AUTOSAR XML (schema 4-0-3)
package /AppSwComponent_Dcm/SwComponentType
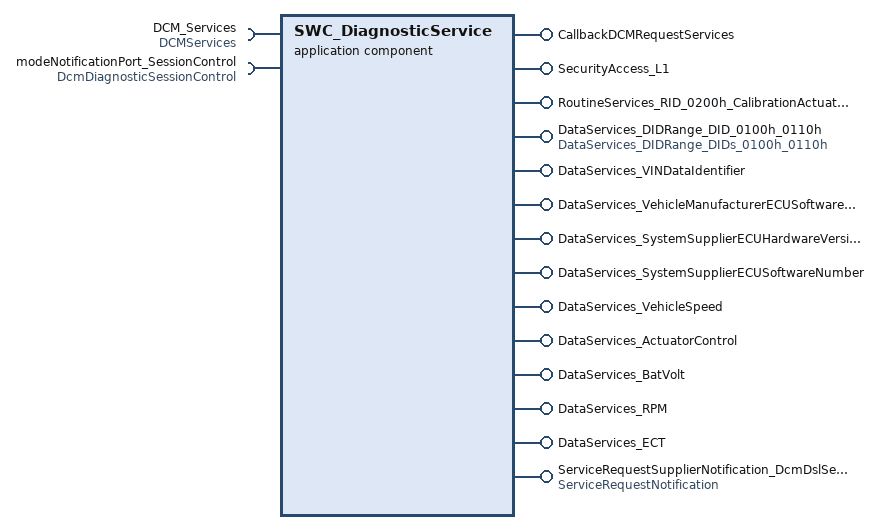
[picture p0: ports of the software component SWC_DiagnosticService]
  application sw component type SWC_DiagnosticService
    4 x provide port:
      CallbackDCMRequestServices: provided-com-specs=[{operation=StartProtocol, queue-length=1}, {operation=StopProtocol, queue-length=1}], provided-interface=CallbackDCMRequestServices
      SecurityAccess_L1: provided-com-specs=[{operation=GetSeed, queue-length=1}, {operation=CompareKey, queue-length=1}], provided-interface=SecurityAccess_L1
      RoutineServices_RID_0200h_CalibrationActuator: provided-interface=RoutineServices_RID_0200h_CalibrationActuator
        provided-com-specs:
          operation=Start, queue-length=1
          operation=Stop, queue-length=1
          operation=RequestResults, queue-length=1
      DataServices_DIDRange_DID_0100h_0110h: provided-interface=DataServices_DIDRange_DIDs_0100h_0110h
        provided-com-specs:
          operation=ReadDidData, queue-length=1
          operation=WriteDidData, queue-length=1
          operation=IsDidAvailable, queue-length=1
    require port DCM_Services: required-com-specs=[GetActiveProtocol, GetSesCtrlType, GetSecurityLevel, ResetToDefaultSession], required-interface=DCMServices
    10 x provide port:
      DataServices_VINDataIdentifier: provided-interface=DataServices_VINDataIdentifier
        provided-com-specs:
          operation=ReadData, queue-length=1
          operation=ConditionCheckRead, queue-length=1
          operation=WriteData, queue-length=1
          operation=GetScalingInformation, queue-length=1
      DataServices_VehicleManufacturerECUSoftwareVersionNumber: provided-com-specs=[{operation=ReadData, queue-length=1}, {operation=ConditionCheckRead, queue-length=1}], provided-interface=DataServices_VehicleManufacturerECUSoftwareVersionNumber
      DataServices_SystemSupplierECUHardwareVersionNumber: provided-com-specs=[{operation=ReadData, queue-length=1}, {operation=ConditionCheckRead, queue-length=1}], provided-interface=DataServices_SystemSupplierECUHardwareVersionNumber
      DataServices_SystemSupplierECUSoftwareNumber: provided-com-specs=[{operation=ReadData, queue-length=1}, {operation=ConditionCheckRead, queue-length=1}], provided-interface=DataServices_SystemSupplierECUSoftwareNumber
      DataServices_VehicleSpeed: provided-interface=DataServices_VehicleSpeed
        provided-com-specs:
          operation=ReadData, queue-length=1
          operation=ConditionCheckRead, queue-length=1
          operation=GetScalingInformation, queue-length=1
      DataServices_ActuatorControl: provided-interface=DataServices_ActuatorControl
        provided-com-specs:
          operation=ConditionCheckRead, queue-length=1
          operation=ReadData, queue-length=1
          operation=ReturnControlToECU, queue-length=1
          operation=ResetToDefault, queue-length=1
          operation=FreezeCurrentState, queue-length=1
          operation=ShortTermAdjustment, queue-length=1
          operation=WriteData, queue-length=1
      DataServices_BatVolt: provided-interface=DataServices_BatVolt
        provided-com-specs:
          operation=ReadData, queue-length=1
          operation=ConditionCheckRead, queue-length=1
          operation=WriteData, queue-length=1
      DataServices_RPM: provided-interface=DataServices_RPM
        provided-com-specs:
          operation=ReadData, queue-length=1
          operation=ConditionCheckRead, queue-length=1
          operation=FreezeCurrentState, queue-length=1
          operation=ReturnControlToECU, queue-length=1
          operation=ShortTermAdjustment, queue-length=1
          operation=WriteData, queue-length=1
      DataServices_ECT: provided-interface=DataServices_ECT
        provided-com-specs:
          operation=ReadData, queue-length=1
          operation=ConditionCheckRead, queue-length=1
          operation=WriteData, queue-length=1
      ServiceRequestSupplierNotification_DcmDslServiceRequestSupplierNotification0: provided-com-specs=[{operation=Confirmation, queue-length=1}, {operation=Indication, queue-length=1}], provided-interface=ServiceRequestNotification
    require port modeNotificationPort_SessionControl: mode-switch-receiver-com-spec{enhanced-mode-api=true, mode-group=DcmDiagnosticSessionControl, supports-asynchronous-mode-switch=true}, required-interface=DcmDiagnosticSessionControl
    behavior InternalBehaviors_DiagnosticService
      44 x operation invoked event:
        OIE_CallbackDCMRequestServices_StartProtocol: start-on-event=CallbackDCMRequestServices_StartProtocol, operation=CallbackDCMRequestServices.StartProtocol
        OIE_CallbackDCMRequestServices_StopProtocol: start-on-event=CallbackDCMRequestServices_StopProtocol, operation=CallbackDCMRequestServices.StopProtocol
        OIE_L1_GetSeed: start-on-event=L1_GetSeed, operation=SecurityAccess_L1.GetSeed
        OIE_L1_CompareKey: start-on-event=L1_CompareKey, operation=SecurityAccess_L1.CompareKey
        OIE_RID_0200h_CalibrationActuator_Start: start-on-event=RID_0200h_CalibrationActuator_Start, operation=RoutineServices_RID_0200h_CalibrationActuator.Start
        OIE_RID_0200h_CalibrationActuator_Stop: start-on-event=RID_0200h_CalibrationActuator_Stop, operation=RoutineServices_RID_0200h_CalibrationActuator.Stop
        OIE_RID_0200h_CalibrationActuator_RequestResults: start-on-event=RID_0200h_CalibrationActuator_RequestResults, operation=RoutineServices_RID_0200h_CalibrationActuator.RequestResults
        OIE_DID_0100h_0110h_ReadDidData: start-on-event=DID_0100h_0110h_ReadDidData, operation=DataServices_DIDRange_DID_0100h_0110h.ReadDidData
        OIE_DID_0100h_0110h_WriteDidData: start-on-event=DID_0100h_0110h_WriteDidData, operation=DataServices_DIDRange_DID_0100h_0110h.WriteDidData
        OIE_DID_0100h_0110h_IsDidAvailable: start-on-event=DID_0100h_0110h_IsDidAvailable, operation=DataServices_DIDRange_DID_0100h_0110h.IsDidAvailable
        OIE_ActuatorControl_ReadData: start-on-event=ActuatorControl_ReadData, operation=DataServices_ActuatorControl.ReadData
        OIE_ActuatorControl_WriteData: start-on-event=ActuatorControl_WriteData, operation=DataServices_ActuatorControl.WriteData
        OIE_ActuatorControl_ConditionCheckRead: start-on-event=ActuatorControl_ConditionCheckRead, operation=DataServices_ActuatorControl.ConditionCheckRead
        OIE_ActuatorControl_ReturnControlToECU: start-on-event=ActuatorControl_ReturnControlToECU, operation=DataServices_ActuatorControl.ReturnControlToECU
        OIE_ActuatorControl_ResetToDefault: start-on-event=ActuatorControl_ResetToDefault, operation=DataServices_ActuatorControl.ResetToDefault
        OIE_ActuatorControl_FreezeCurrentState: start-on-event=ActuatorContro_FreezeCurrentState, operation=DataServices_ActuatorControl.FreezeCurrentState
        OIE_ActuatorControl_ShortTermAdjustment: start-on-event=ActuatorControl_ShortTermAdjustment, operation=DataServices_ActuatorControl.ShortTermAdjustment
        OIE_VINDataIdentifier_ReadData: start-on-event=VINDataIdentifier_ReadData, operation=DataServices_VINDataIdentifier.ReadData
        OIE_VINDataIdentifier_ConditionCheckRead: start-on-event=VINDataIdentifier_ConditionCheckRead, operation=DataServices_VINDataIdentifier.ConditionCheckRead
        OIE_VINDataIdentifier_WriteData: start-on-event=VINDataIdentifier_WriteData, operation=DataServices_VINDataIdentifier.WriteData
        OIE_VINDataIdentifier_GetScalingInformation: start-on-event=VINDataIdentifier_GetScalingInformation, operation=DataServices_VINDataIdentifier.GetScalingInformation
        OIE_VehicleManufacturerECUSoftwareVersionNumber_ReadData: start-on-event=VehicleManufacturerECUSoftwareVersionNumber_ReadData, operation=DataServices_VehicleManufacturerECUSoftwareVersionNumber.ReadData
        OIE_VehicleManufacturerECUSoftwareVersionNumber_ConditionCheckRead: start-on-event=VehicleManufacturerECUSoftwareVersionNumber_ConditionCheckRead, operation=DataServices_VehicleManufacturerECUSoftwareVersionNumber.ConditionCheckRead
        OIE_SystemSupplierECUHardwareVersionNumber_ReadData: start-on-event=SystemSupplierECUHardwareVersionNumber_ReadData, operation=DataServices_SystemSupplierECUHardwareVersionNumber.ReadData
        OIE_SystemSupplierECUHardwareVersionNumber_ConditionCheckRead: start-on-event=SystemSupplierECUHardwareVersionNumber_ConditionCheckRead, operation=DataServices_SystemSupplierECUHardwareVersionNumber.ConditionCheckRead
        OIE_SystemSupplierECUSoftwareNumber_ReadData: start-on-event=SystemSupplierECUSoftwareNumber_ReadData, operation=DataServices_SystemSupplierECUSoftwareNumber.ReadData
        OIE_SystemSupplierECUSoftwareNumber_ConditionCheckRead: start-on-event=SystemSupplierECUSoftwareNumber_ConditionCheckRead, operation=DataServices_SystemSupplierECUSoftwareNumber.ConditionCheckRead
        OIE_VehicleSpeed_ReadData: start-on-event=VehicleSpeed_ReadData, operation=DataServices_VehicleSpeed.ReadData
        OIE_VehicleSpeed_ConditionCheckRead: start-on-event=VehicleSpeed_ConditionCheckRead, operation=DataServices_VehicleSpeed.ConditionCheckRead
        OIE_VehicleSpeed_GetScalingInformation: start-on-event=VehicleSpeed_GetScalingInformation, operation=DataServices_VehicleSpeed.GetScalingInformation
        OIE_BatVolt_ReadData: start-on-event=BatVolt_ReadData, operation=DataServices_BatVolt.ReadData
        OIE_BatVolt_WriteData: start-on-event=BatVolt_WriteData, operation=DataServices_BatVolt.WriteData
        OIE_BatVolt_ConditionCheckRead: start-on-event=BatVolt_ConditionCheckRead, operation=DataServices_BatVolt.ConditionCheckRead
        OIE_ECT_ReadData: start-on-event=ECT_ReadData, operation=DataServices_ECT.ReadData
        OIE_ECT_ConditionCheckRead: start-on-event=ECT_ConditionCheckRead, operation=DataServices_ECT.ConditionCheckRead
        OIE_ECT_WriteData: start-on-event=ECT_WriteData, operation=DataServices_ECT.WriteData
        OIE_RPM_ConditionCheckRead: start-on-event=RPM_ConditionCheckRead, operation=DataServices_RPM.ConditionCheckRead
        OIE_RPM_ReadData: start-on-event=RPM_ReadData, operation=DataServices_RPM.ReadData
        OIE_RPM_ShortTermAdjustment: start-on-event=RPM_ShortTermAdjustment, operation=DataServices_RPM.ShortTermAdjustment
        OIE_RPM_ReturnControlToECU: start-on-event=RPM_ReturnControlToECU, operation=DataServices_RPM.ReturnControlToECU
        OIE_RPM_FreezeCurrentState: start-on-event=RPM_FreezeCurrentState, operation=DataServices_RPM.FreezeCurrentState
        OIE_RPM_WriteData: start-on-event=RPM_WriteData, operation=DataServices_RPM.WriteData
        OIE_ServiceRequestSupplierNotification_Confirmation: start-on-event=ServiceRequestSupplierNotification_Confirmation, operation=ServiceRequestSupplierNotification_DcmDslServiceRequestSupplierNotification0.Confirmation
        OIE_ServiceRequestSupplierNotification_Indication: start-on-event=ServiceRequestSupplierNotification_Indication, operation=ServiceRequestSupplierNotification_DcmDslServiceRequestSupplierNotification0.Indication
      swc mode switch event SMSE_Entry_DiagnosticSessionControlNotification_modeNotificationPort_SessionControl_DcmDiagnosticSessionControl_DCM_DEFAULT_SESSION: start-on-event=DiagnosticSessionControlNotification, activation=ON-ENTRY, mode=modeNotificationPort_SessionControl.DcmDiagnosticSessionControl.DCM_DEFAULT_SESSION
      swc mode switch event SMSE_Entry_DiagnosticSessionControlNotification_modeNotificationPort_SessionControl_DcmDiagnosticSessionControl_DCM_EXTENDED_DIAGNOSTIC_SESSION: start-on-event=DiagnosticSessionControlNotification, activation=ON-ENTRY, mode=modeNotificationPort_SessionControl.DcmDiagnosticSessionControl.DCM_EXTENDED_DIAGNOSTIC_SESSION
      46 x runnable, all with can-be-invoked-concurrently=true:
        DO_NOT_REMPOVE: symbol=AppDcm_Runnable
          4 x sync call:
            SSCP_GetActiveProtocol: operation=DCM_Services.GetActiveProtocol
            SSCP_GetSesCtrlType: operation=DCM_Services.GetSesCtrlType
            SSCP_GetSecurityLevel: operation=DCM_Services.GetSecurityLevel
            SSCP_ResetToDefaultSession: operation=DCM_Services.ResetToDefaultSession
        CallbackDCMRequestServices_StartProtocol: symbol=AppDcm_StartProtocol
        CallbackDCMRequestServices_StopProtocol: symbol=AppDcm_StopProtocol
        DID_0100h_0110h_ReadDidData: symbol=AppDcm_ReadDidData_DID_0100h_0110h
        DID_0100h_0110h_WriteDidData: symbol=AppDcm_WriteDidData_DID_0100h_0110h
        DID_0100h_0110h_IsDidAvailable: symbol=AppDcm_IsDidAvailable_DID_0100h_0110h
        L1_GetSeed: symbol=AppDcm_GetSeed_L1
        L1_CompareKey: symbol=AppDcm_CompareKey_L1
        RID_0200h_CalibrationActuator_Start: symbol=AppDcm_Start_CalibrationActuator
        RID_0200h_CalibrationActuator_Stop: symbol=AppDcm_Stop_CalibrationActuator
        RID_0200h_CalibrationActuator_RequestResults: symbol=AppDcm_RequestResults_CalibrationActuator
        VINDataIdentifier_ReadData: symbol=AppDcm_ReadData_VINDataIdentifier
        VINDataIdentifier_ConditionCheckRead: symbol=AppDcm_ConditionCheckRead_VINDataIdentifier
        VINDataIdentifier_WriteData: symbol=AppDcm_WriteData_VINDataIdentifier
        VINDataIdentifier_GetScalingInformation: symbol=AppDcm_GetScalingInformation_VINDataIdentifier
        VehicleManufacturerECUSoftwareVersionNumber_ReadData: symbol=AppDcm_ReadData_VehicleManufacturerECUSoftwareVersionNumber
        VehicleManufacturerECUSoftwareVersionNumber_ConditionCheckRead: symbol=AppDcm_ConditionCheckRead_VehicleManufacturerECUSoftwareVersionNumber
        SystemSupplierECUHardwareVersionNumber_ReadData: symbol=AppDcm_ReadData_SystemSupplierECUHardwareVersionNumber
        SystemSupplierECUHardwareVersionNumber_ConditionCheckRead: symbol=AppDcm_ConditionCheckRead_SystemSupplierECUHardwareVersionNumber
        SystemSupplierECUSoftwareNumber_ReadData: symbol=AppDcm_ReadData_SystemSupplierECUSoftwareNumber
        SystemSupplierECUSoftwareNumber_ConditionCheckRead: symbol=AppDcm_ConditionCheckRead_SystemSupplierECUSoftwareNumber
        VehicleSpeed_ReadData: symbol=AppDcm_ReadData_VehicleSpeed
        VehicleSpeed_ConditionCheckRead: symbol=AppDcm_ConditionCheckRead_VehicleSpeed
        VehicleSpeed_GetScalingInformation: symbol=AppDcm_GetScalingInformation_VehicleSpeed
        ActuatorControl_ReadData: symbol=AppDcm_ReadData_ActuatorControl
        ActuatorControl_WriteData: symbol=AppDcm_WriteData_ActuatorControl
        ActuatorControl_ConditionCheckRead: symbol=AppDcm_ConditionCheckRead_ActuatorControl
        ActuatorControl_ReturnControlToECU: symbol=AppDcm_ReturnControlToECU_ActuatorControl
        ActuatorControl_ResetToDefault: symbol=AppDcm_ResetToDefault_ActuatorControl
        ActuatorContro_FreezeCurrentState: symbol=AppDcm_FreezeCurrentState_ActuatorControl
        ActuatorControl_ShortTermAdjustment: symbol=AppDcm_ShortTermAdjustment_ActuatorControl
        BatVolt_ConditionCheckRead: symbol=AppDcm_ConditionCheckRead_BatVolt
        BatVolt_ReadData: symbol=AppDcm_ReadData_BatVolt
        BatVolt_WriteData: symbol=AppDcm_WriteData_BatVolt
        ECT_ConditionCheckRead: symbol=AppDcm_ConditionCheckRead_ECT
        ECT_ReadData: symbol=AppDcm_ReadData_ECT
        ECT_WriteData: symbol=AppDcm_WriteData_ECT
        RPM_ConditionCheckRead: symbol=AppDcm_ConditionCheckRead_RPM
        RPM_ReadData: symbol=AppDcm_ReadData_RPM
        RPM_ShortTermAdjustment: symbol=AppDcm_ShortTermAdjustment_RPM
        RPM_ReturnControlToECU: symbol=AppDcm_ReturnControlToECU_RPM
        RPM_FreezeCurrentState: symbol=AppDcm_FreezeCurrentState_RPM
        RPM_WriteData: symbol=AppDcm_WriteData_RPM
        ServiceRequestSupplierNotification_Confirmation
        ServiceRequestSupplierNotification_Indication
        DiagnosticSessionControlNotification: symbol=AppDcm_DiagnosticSessionControlNotification
          mode-access-point mode-group=modeNotificationPort_SessionControl.DcmDiagnosticSessionControl:
            ident MRAP_DiagnosticSessionControlNotification_modeNotificationPort_SessionControl_DcmDiagnosticSessionControl
      swc service dependency SwcServiceDependency0: assigned-ports=role-based-port-assignment={port-prototype=modeNotificationPort_SessionControl, role=Custom}
        service-needs:
          bsw mgr needs BswMgrNeeds
  swc implementation App_Dcm_Implementation: behavior=InternalBehaviors_DiagnosticService
    code-descriptors:
      code Default
